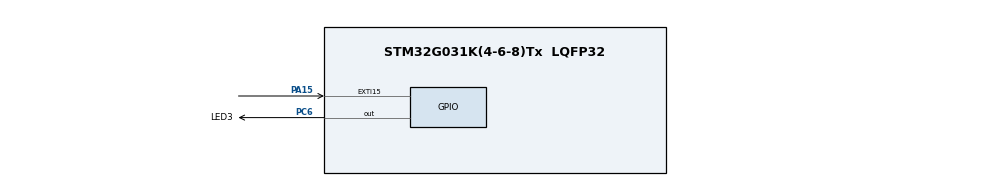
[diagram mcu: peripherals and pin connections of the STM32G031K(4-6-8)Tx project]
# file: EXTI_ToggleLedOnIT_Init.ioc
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Mcu.Family=STM32G0
Mcu.Name=STM32G031K(4-6-8)Tx
Mcu.Package=LQFP32
NVIC.EXTI4_15_IRQn=true\:0\:0\:false\:false\:true\:true\:true\:true
PA15.GPIO_PuPd=GPIO_PULLUP
PA15.Signal=GPXTI15
PC6.GPIO_Label=LED3
PC6.Signal=GPIO_Output
ProjectManager.HeapSize=0x200
ProjectManager.StackSize=0x400
ProjectManager.TargetToolchain=EWARM V8.50
RCC.ADCFreq_Value=16000000
RCC.AHBFreq_Value=16000000
RCC.CortexFreq_Value=16000000
RCC.EXTERNAL_CLOCK_VALUE=48000000
RCC.HCLKFreq_Value=16000000
RCC.HSE_VALUE=8000000
RCC.HSI_VALUE=16000000
RCC.LSE_VALUE=32768
RCC.SYSCLKFreq_VALUE=16000000
RCC.VCOOutputFreq_Value=128000000
board=NUCLEO-G031K8

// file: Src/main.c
/* USER CODE BEGIN Header */
/**
  ******************************************************************************
  * @file    Examples_LL/EXTI/EXTI_ToggleLedOnIT_Init/Src/main.c
  * @author  MCD Application Team
  * @brief   This example describes how to configure the EXTI and use
  *          GPIOs using the STM32G0xx LL API to toggles the available
  *          users Leds on the board when User button is pressed.
  *          Peripheral initialization done using LL initialization function.
  ******************************************************************************
  * @attention
  *
  * Copyright (c) 2019-2020 STMicroelectronics.
  * All rights reserved.
  *
  * This software is licensed under terms that can be found in the LICENSE file
  * in the root directory of this software component.
  * If no LICENSE file comes with this software, it is provided AS-IS.
  *
  ******************************************************************************
  */
/* USER CODE END Header */
#include "main.h"
#include "app.h"

/* USER CODE BEGIN PV */
/* Debounce delay */
static uint32_t Wait200ms = 0;
/* USER CODE END PV */

void SystemClock_Config(void);
static void MX_GPIO_Init(void);

int main(void)
{

  /* MCU Configuration--------------------------------------------------------*/

  /* Reset of all peripherals, Initializes the Flash interface and the Systick. */
  LL_APB2_GRP1_EnableClock(LL_APB2_GRP1_PERIPH_SYSCFG);
  LL_APB1_GRP1_EnableClock(LL_APB1_GRP1_PERIPH_PWR);

  /* Configure the system clock */
  SystemClock_Config();

  /* Initialize all configured peripherals */
  MX_GPIO_Init();

  /* Infinite loop */
  /* USER CODE BEGIN WHILE */
  while (1)
  {
    if (Wait200ms == 1)
    {
      /* Wait 200 ms */
      LL_mDelay(200);

      /* Clear debounce flag */
      Wait200ms = 0;
    }
    /* USER CODE END WHILE */

  }
}

void SystemClock_Config(void)
{
  /* HSI configuration and activation */
  LL_RCC_HSI_Enable();
  while(LL_RCC_HSI_IsReady() != 1)
  {
  }

  /* Set AHB prescaler*/
  LL_RCC_SetAHBPrescaler(LL_RCC_SYSCLK_DIV_1);

  /* Sysclk activation on the HSI */
  LL_RCC_SetSysClkSource(LL_RCC_SYS_CLKSOURCE_HSI);
  while(LL_RCC_GetSysClkSource() != LL_RCC_SYS_CLKSOURCE_STATUS_HSI)
  {
  }

  /* Set APB1 prescaler*/
  LL_RCC_SetAPB1Prescaler(LL_RCC_APB1_DIV_1);

  LL_Init1msTick(16000000);

  /* Update CMSIS variable (which can be updated also through SystemCoreClockUpdate function) */
  LL_SetSystemCoreClock(16000000);
}

static void MX_GPIO_Init(void)
{
  LL_EXTI_InitTypeDef EXTI_InitStruct = {0};
  LL_GPIO_InitTypeDef GPIO_InitStruct = {0};

  /* GPIO Ports Clock Enable */
  LL_IOP_GRP1_EnableClock(LL_IOP_GRP1_PERIPH_GPIOC);
  LL_IOP_GRP1_EnableClock(LL_IOP_GRP1_PERIPH_GPIOA);

  /**/
  LL_GPIO_ResetOutputPin(LED3_GPIO_Port, LED3_Pin);

  /**/
  GPIO_InitStruct.Pin = LED3_Pin;
  GPIO_InitStruct.Mode = LL_GPIO_MODE_OUTPUT;
  GPIO_InitStruct.Speed = LL_GPIO_SPEED_FREQ_LOW;
  GPIO_InitStruct.OutputType = LL_GPIO_OUTPUT_PUSHPULL;
  GPIO_InitStruct.Pull = LL_GPIO_PULL_NO;
  LL_GPIO_Init(LED3_GPIO_Port, &GPIO_InitStruct);

  /**/
  LL_EXTI_SetEXTISource(LL_EXTI_CONFIG_PORTA, LL_EXTI_CONFIG_LINE15);

  /**/
  EXTI_InitStruct.Line_0_31 = LL_EXTI_LINE_15;
  EXTI_InitStruct.LineCommand = ENABLE;
  EXTI_InitStruct.Mode = LL_EXTI_MODE_IT;
  EXTI_InitStruct.Trigger = LL_EXTI_TRIGGER_RISING;
  LL_EXTI_Init(&EXTI_InitStruct);

  /**/
  LL_GPIO_SetPinPull(GPIOA, LL_GPIO_PIN_15, LL_GPIO_PULL_UP);

  /**/
  LL_GPIO_SetPinMode(GPIOA, LL_GPIO_PIN_15, LL_GPIO_MODE_INPUT);

  /* EXTI interrupt init*/
  NVIC_SetPriority(EXTI4_15_IRQn, 0);
  NVIC_EnableIRQ(EXTI4_15_IRQn);

}

/* USER CODE BEGIN 4 */

/******************************************************************************/
/*   USER IRQ HANDLER TREATMENT                                               */
/******************************************************************************/
/**
  * @brief  Function to manage IRQ Handler
  * @param  None
  * @retval None
  */
void UserButton_Callback(void)
{
  if (Wait200ms == 0)
  {
    /* Set debounce flag */
    Wait200ms = 1;

    LL_GPIO_TogglePin(LED3_GPIO_Port, LED3_Pin);
  }
}

/* USER CODE END 4 */

void Error_Handler(void)
{
}
